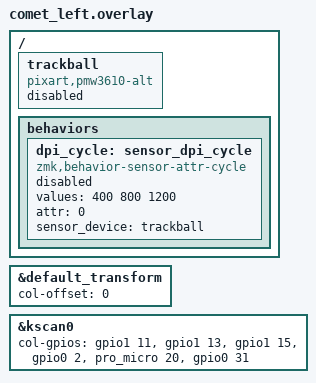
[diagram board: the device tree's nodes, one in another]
/*
 * Copyright (c) 2026 The ZMK Contributors
 *
 * SPDX-License-Identifier: MIT
 */

#include "comet.dtsi"

/ {
    trackball: trackball {
        status = "disabled";
        compatible = "pixart,pmw3610-alt";
    };

    behaviors {
        dpi_cycle: sensor_dpi_cycle {
            compatible = "zmk,behavior-sensor-attr-cycle";
            #binding-cells = <1>;
            values = <400 800 1200>;
            attr = <0>;
            sensor_device = <&trackball>;
            status = "disabled";
        };
    };
};

&default_transform {
    col-offset = <0>;
};

&kscan0 {
    col-gpios
        = <&gpio1 11 GPIO_ACTIVE_HIGH>  // P0.31 (A0/D14) - outer
        , <&gpio1 13 GPIO_ACTIVE_HIGH>  // P0.29 (A1/D15) - pinky
        , <&gpio1 15 GPIO_ACTIVE_HIGH>   // P0.02 (A2/D16) - ring
        , <&gpio0 2 GPIO_ACTIVE_HIGH>  // P1.15 (A3/D17) - middle
        , <&pro_micro 20 GPIO_ACTIVE_HIGH>  // P1.13 (D18) - index
        , <&gpio0 31 GPIO_ACTIVE_HIGH>  // P1.10 (D19) - inner
        ;
};
